# AT32F421xx register map
Vendor: Keil; Series: AT32F421; File version: 1.0
CPU: CM4 r0p1, little endian, no MPU, FPU, 4 interrupt priority bits
Registers are 32-bit, read-write, reset 0x0 unless marked. A register's access mark holds for its fields unless they carry their own. Offsets are from the block's base; [hi:lo] are bit positions; {n}, {i} and the like mark numbered series; 'fields as' and 'values as' point back to an identical list.

## GPIOA — General purpose I/Os
Base 0x48000000
Same registers: GPIOB 0x48000400, GPIOC 0x48000800, GPIOF 0x48001400
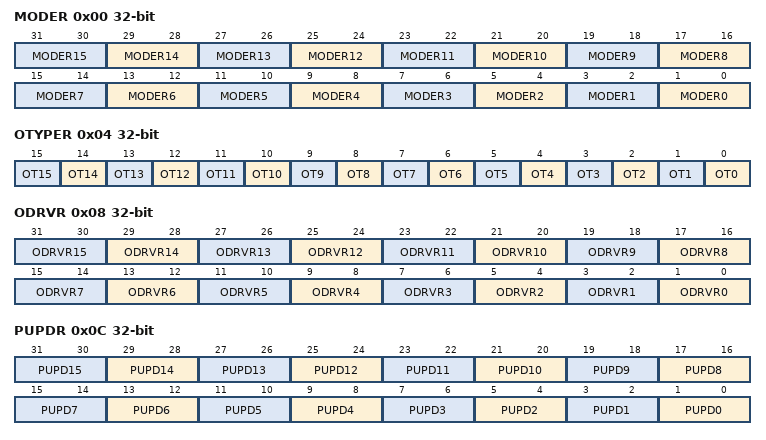
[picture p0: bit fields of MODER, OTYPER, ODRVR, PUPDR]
0x00 MODER — GPIO port mode register
  [2n+1:2n] MODER{n} (n=0..15) — Port x configuration bits (y = 0..15)
0x04 OTYPER — GPIO port output type register
  [n] OT{n} (n=0..15) — Port x configuration bit {n}
0x08 ODRVR — GPIO port output speed register
  [2n+1:2n] ODRVR{n} (n=0..15) — Port x configuration bits (y = 0..15)
0x0C PUPDR — GPIO port pull-up/pull-down register
  [2n+1:2n] PUPD{n} (n=0..15) — Port x configuration bits (y = 0..15)
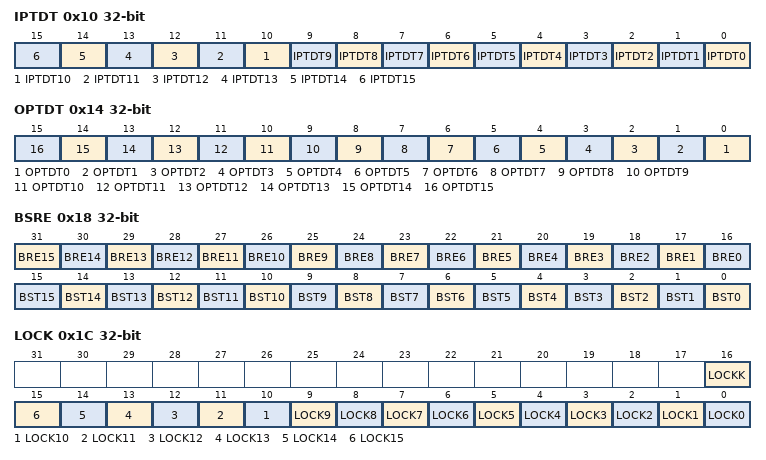
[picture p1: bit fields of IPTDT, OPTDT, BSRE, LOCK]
0x10 IPTDT ro — GPIO port input data register
  [n] IPTDT{n} (n=0..15) — Port input data (y = 0..15)
0x14 OPTDT — GPIO port output data register
  [n] OPTDT{n} (n=0..15) — Port output data (y = 0..15)
0x18 BSRE wo — GPIO port bit set/reset register
  [n+16] BRE{n} (n=1..15) — Port x reset bit y (y = 0..15)
  [16] BRE0 — Port x set bit y (y= 0..15)
  [n] BST{n} (n=0..15) — Port x set bit y (y= 0..15)
0x1C LOCK — GPIO port configuration lock register
  [16] LOCKK — Port x lock bit y
  [n] LOCK{n} (n=0..15) — Port x lock bit y (y= 0..15)
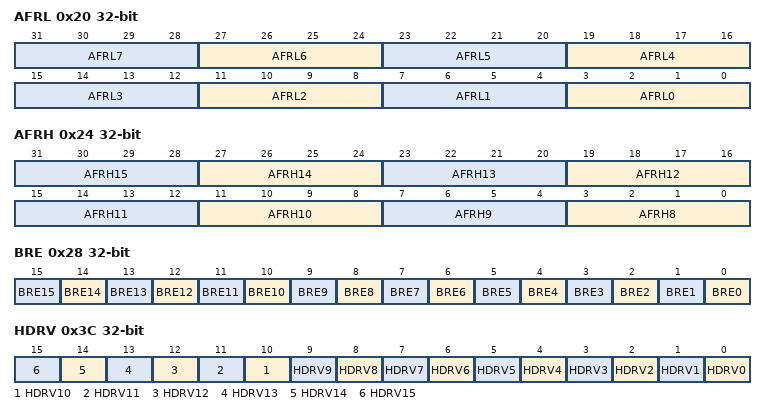
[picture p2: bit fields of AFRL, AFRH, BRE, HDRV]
0x20 AFRL — GPIO alternate function low register
  [4n+3:4n] AFRL{n} (n=0..7) — Alternate function selection for port x bit y (y = 0..7)
0x24 AFRH — GPIO alternate function high register
  [4n-29:4n-32] AFRH{n} (n=8..15) — Alternate function selection for port x bit y (y = 8..15)
0x28 BRE wo — Port bit reset register
  [n] BRE{n} (n=0..15) — Port x Reset bit y
0x3C HDRV — Huge current driver
  [n] HDRV{n} (n=0..15) — Port x driver bit y
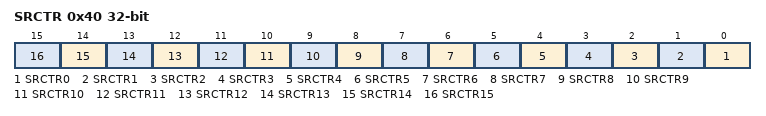
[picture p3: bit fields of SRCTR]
0x40 SRCTR — Voltage swtich rate ctrl
  [n] SRCTR{n} (n=0..15) — Port x switch rate bit y

## EXTI
Base 0x40010400
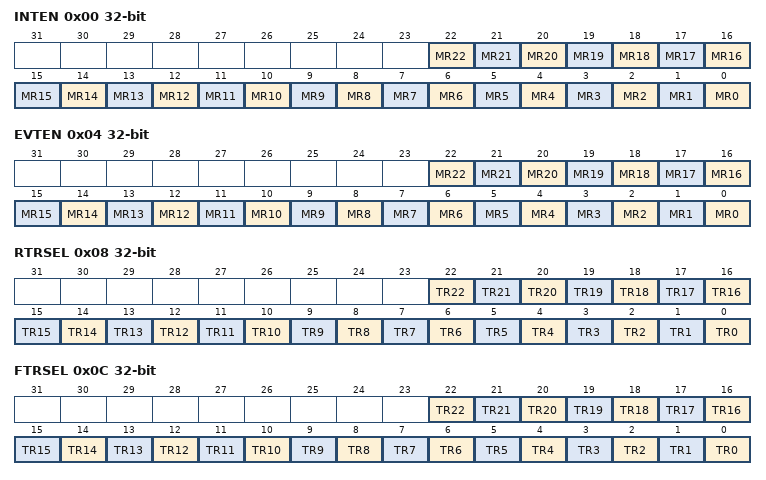
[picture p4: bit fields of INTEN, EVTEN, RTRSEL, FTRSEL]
0x00 INTEN — Interrupt mask register (EXTI_INTEN)
  [n] MR{n} (n=0..22) — Interrupt Mask on line {n}
0x04 EVTEN — Event mask register (EXTI_EVTEN)
  [n] MR{n} (n=0..22) — Event Mask on line {n}
0x08 RTRSEL — Rising Trigger selection register (EXTI_RTRSEL)
  [n] TR{n} (n=0..22) — Rising trigger event configuration of line {n}
0x0C FTRSEL — Falling Trigger selection register (EXTI_FTRSEL)
  [n] TR{n} (n=0..22) — Falling trigger event configuration of line {n}
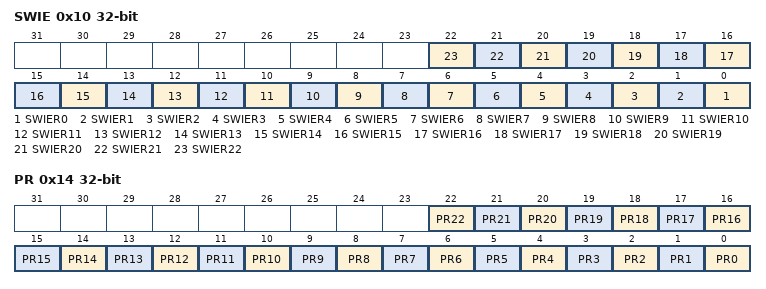
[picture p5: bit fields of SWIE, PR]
0x10 SWIE — Software interrupt event register (EXTI_SWIE)
  [n] SWIER{n} (n=0..22) — Software Interrupt on line {n}
0x14 PR — Pending register (EXTI_PR)
  [n] PR{n} (n=0..22) — Pending bit {n}

## DMA1 — DMA controller
Base 0x40020000
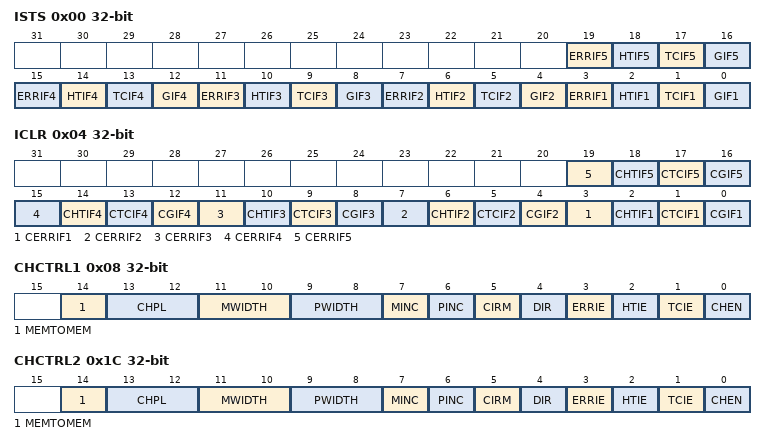
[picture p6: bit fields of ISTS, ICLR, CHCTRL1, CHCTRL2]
0x00 ISTS ro — DMA interrupt status register (DMA_ISTS)
  [4n-1] ERRIF{n} (n=1..5) — Channel {n} Transfer Error flag
  [4n-2] HTIF{n} (n=1..5) — Channel {n} Half Transfer Complete flag
  [4n-3] TCIF{n} (n=1..5) — Channel {n} Transfer Complete flag
  [4n-4] GIF{n} (n=1..5) — Channel {n} Global interrupt flag
0x04 ICLR — DMA interrupt flag clear register (DMA_ICLR)
  [4n-1] CERRIF{n} (n=1..5) — Channel {n} Transfer Error clear
  [4n-2] CHTIF{n} (n=1..5) — Channel {n} Half Transfer clear
  [4n-3] CTCIF{n} (n=1..5) — Channel {n} Transfer Complete clear
  [4n-4] CGIF{n} (n=1..5) — Channel {n} Global interrupt clear
0x08 CHCTRL1 — DMA channel configuration register (DMA_CCR)
  [14] MEMTOMEM — Memory to memory mode
  [13:12] CHPL — Channel Priority level
  [11:10] MWIDTH — Memory size
  [9:8] PWIDTH — Peripheral size
  [7] MINC — Memory increment mode
  [6] PINC — Peripheral increment mode
  [5] CIRM — Circular mode
  [4] DIR — Data transfer direction
  [3] ERRIE — Transfer error interrupt enable
  [2] HTIE — Half Transfer interrupt enable
  [1] TCIE — Transfer complete interrupt enable
  [0] CHEN — Channel enable
0x0C TCNT1 — DMA channel 1 number of data register
  [15:0] CNT — Number of data to transfer
0x10 CPBA1 — DMA channel 1 peripheral address register
  [31:0] PA — Peripheral address
{0x0+0x14*i} CMBA{i} (i=1..5) — DMA channel {i} memory address register
  [31:0] MA — Memory address
0x1C CHCTRL2 — DMA channel configuration register (DMA_CHCTRL2)
  fields as CHCTRL1
0x20 TCNT2 — DMA channel 2 number of data register
  [15:0] CNT — Number of data to transfer
0x24 CPBA2 — DMA channel 2 peripheral address register
  [31:0] PA — Peripheral address
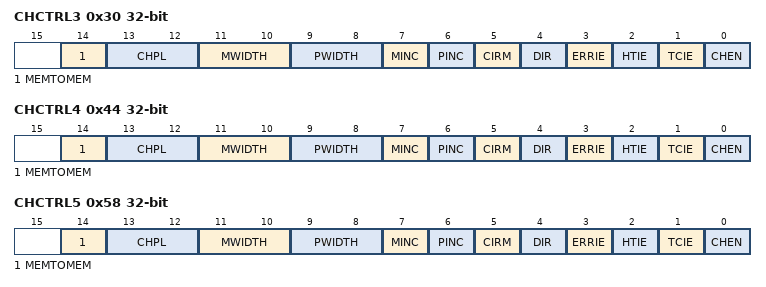
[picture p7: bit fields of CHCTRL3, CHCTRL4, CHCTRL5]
0x30 CHCTRL3 — DMA channel configuration register (DMA_CHCTRL3)
  fields as CHCTRL1
0x34 TCNT3 — DMA channel 3 number of data register
  [15:0] CNT — Number of data to transfer
0x38 CPBA3 — DMA channel 3 peripheral address register
  [31:0] PA — Peripheral address
0x44 CHCTRL4 — DMA channel configuration register (DMA_CHCTRL4)
  fields as CHCTRL1
0x48 TCNT4 — DMA channel 4 number of data register
  [15:0] CNT — Number of data to transfer
0x4C CPBA4 — DMA channel 4 peripheral address register
  [31:0] PA — Peripheral address
0x58 CHCTRL5 — DMA channel configuration register (DMA_CHCTRL5)
  fields as CHCTRL1
0x5C TCNT5 — DMA channel 5 number of data register
  [15:0] CNT — Number of data to transfer
0x60 CPBA5 — DMA channel 5 peripheral address register
  [31:0] PA — Peripheral address
